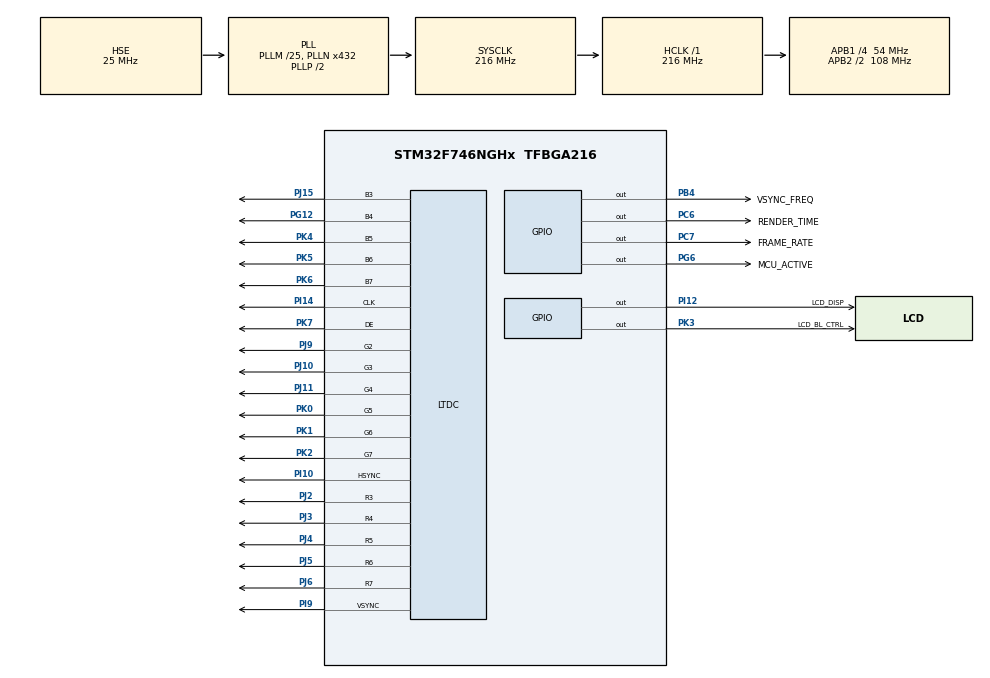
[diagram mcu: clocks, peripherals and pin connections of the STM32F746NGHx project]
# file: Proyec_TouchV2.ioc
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CORTEX_M7.CPU_DCache=Enabled
CORTEX_M7.CPU_ICache=Enabled
CORTEX_M7.default_mode_Activation=1
LTDC.ActiveH=100
LTDC.ActiveW=400
LTDC.Alpha_L0=255
LTDC.Blue_L0=0x00
LTDC.FBStartAdress_L0=0xC0000000
LTDC.Green_L0=0x00
LTDC.HBP=13
LTDC.HFP=32
LTDC.HSync=41
LTDC.ImageHeight_L0=100
LTDC.ImageWidth_L0=400
LTDC.Layers=0
LTDC.PixelFormat_L0=LTDC_PIXEL_FORMAT_RGB565
LTDC.Red_L0=0xFF
LTDC.VSync=10
LTDC.WindowX1_L0=400
LTDC.WindowY1_L0=100
Mcu.Family=STM32F7
Mcu.Name=STM32F746NGHx
Mcu.Package=TFBGA216
NVIC.DMA2D_IRQn=true\:0\:0\:false\:false\:true\:true\:true\:true
NVIC.LTDC_IRQn=true\:0\:0\:false\:false\:true\:true\:true\:true
NVIC.PriorityGroup=NVIC_PRIORITYGROUP_4
NVIC.TIM6_DAC_IRQn=true\:15\:0\:false\:false\:true\:false\:true\:true
NVIC.TimeBase=TIM6_DAC_IRQn
NVIC.TimeBaseIP=TIM6
PA13.Mode=Serial_Wire
PA13.Signal=SYS_JTMS-SWDIO
PA14.Mode=Serial_Wire
PA14.Signal=SYS_JTCK-SWCLK
PB4.GPIO_Label=VSYNC_FREQ
PB4.Signal=GPIO_Output
PC3.Signal=FMC_SDCKE0
PC6.GPIO_Label=RENDER_TIME
PC6.Signal=GPIO_Output
PC7.GPIO_Label=FRAME_RATE
PC7.Signal=GPIO_Output
PD11.Signal=QUADSPI_BK1_IO0
PD12.Signal=QUADSPI_BK1_IO1
PD13.Signal=QUADSPI_BK1_IO3
PG12.Mode=RGB565
PG12.Signal=LTDC_B4
PG6.GPIO_Label=MCU_ACTIVE
PG6.Signal=GPIO_Output
PH0/OSC_IN.Mode=HSE-External-Oscillator
PH0/OSC_IN.Signal=RCC_OSC_IN
PH1/OSC_OUT.Mode=HSE-External-Oscillator
PH1/OSC_OUT.Signal=RCC_OSC_OUT
PI10.Mode=RGB565
PI10.Signal=LTDC_HSYNC
PI12.GPIO_Label=LCD_DISP
PI12.PinState=GPIO_PIN_SET
PI12.Signal=GPIO_Output
PI14.Mode=RGB565
PI14.Signal=LTDC_CLK
PI15.Signal=LTDC_R0
PI9.Mode=RGB565
PI9.Signal=LTDC_VSYNC
PJ0.Signal=LTDC_R1
PJ1.Signal=LTDC_R2
PJ10.Mode=RGB565
PJ10.Signal=LTDC_G3
PJ11.Mode=RGB565
PJ11.Signal=LTDC_G4
PJ14.Signal=LTDC_B2
PJ15.Mode=RGB565
PJ15.Signal=LTDC_B3
PJ2.Mode=RGB565
PJ2.Signal=LTDC_R3
PJ3.Mode=RGB565
PJ3.Signal=LTDC_R4
PJ4.Mode=RGB565
PJ4.Signal=LTDC_R5
PJ5.Mode=RGB565
PJ5.Signal=LTDC_R6
PJ6.Mode=RGB565
PJ6.Signal=LTDC_R7
PJ7.Signal=LTDC_G0
PJ8.Signal=LTDC_G1
PJ9.Mode=RGB565
PJ9.Signal=LTDC_G2
PK0.Mode=RGB565
PK0.Signal=LTDC_G5
PK1.Mode=RGB565
PK1.Signal=LTDC_G6
PK2.Mode=RGB565
PK2.Signal=LTDC_G7
PK3.GPIO_Label=LCD_BL_CTRL
PK3.PinState=GPIO_PIN_SET
PK3.Signal=GPIO_Output
PK4.Mode=RGB565
PK4.Signal=LTDC_B5
PK5.Mode=RGB565
PK5.Signal=LTDC_B6
PK6.Mode=RGB565
PK6.Signal=LTDC_B7
PK7.Mode=RGB565
PK7.Signal=LTDC_DE
ProjectManager.HeapSize=0x200
ProjectManager.StackSize=0x400
ProjectManager.TargetToolchain=STM32CubeIDE
RCC.AHBFreq_Value=216000000
RCC.APB1CLKDivider=RCC_HCLK_DIV4
RCC.APB1Freq_Value=54000000
RCC.APB1TimFreq_Value=108000000
RCC.APB2CLKDivider=RCC_HCLK_DIV2
RCC.APB2Freq_Value=108000000
RCC.APB2TimFreq_Value=216000000
RCC.CortexFreq_Value=216000000
RCC.HCLKFreq_Value=216000000
RCC.HSE_VALUE=25000000
RCC.HSI_VALUE=16000000
RCC.LSE_VALUE=32768
RCC.PLLM=25
RCC.PLLN=432
RCC.PLLSAIR=5
RCC.PLLSAIRDiv=RCC_PLLSAIDIVR_4
RCC.PLLSourceVirtual=RCC_PLLSOURCE_HSE
RCC.SYSCLKFreq_VALUE=216000000
RCC.SYSCLKSource=RCC_SYSCLKSOURCE_PLLCLK
RCC.USBFreq_Value=216000000
RCC.VCOOutputFreq_Value=432000000
STMicroelectronics.X-CUBE-TOUCHGFX.4.24.0.tgfx_display_interface=disp_ltdc
STMicroelectronics.X-CUBE-TOUCHGFX.4.24.0.tgfx_hardware_accelerator=dma_2d
STMicroelectronics.X-CUBE-TOUCHGFX.4.24.0.tgfx_oswrapper=CMSIS V2
STMicroelectronics.X-CUBE-TOUCHGFX.4.24.0.tgfx_vector_rendering=Disabled
STMicroelectronics.X-CUBE-TOUCHGFX.4.24.0.tgfx_video=Disabled
STMicroelectronics.X-CUBE-TOUCHGFX.4.24.0.tgfx_video_height=272
STMicroelectronics.X-CUBE-TOUCHGFX.4.24.0.tgfx_video_strategy=2
STMicroelectronics.X-CUBE-TOUCHGFX.4.24.0.tgfx_video_width=480
STMicroelectronics.X-CUBE-TOUCHGFX.4.24.0.tgfx_vsync=vsync_ltdc
STMicroelectronics.X-CUBE-TOUCHGFX.4.24.0_IsPackSelfContextualization=true
VP_CRC_VS_CRC.Mode=CRC_Activate
VP_DMA2D_VS_DMA2D.Mode=DMA2D_Activate
VP_SYS_VS_tim6.Mode=TIM6
board=custom

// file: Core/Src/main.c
/* USER CODE BEGIN Header */
/**
  ******************************************************************************
  * @file           : main.c
  * @brief          : Main program body
  ******************************************************************************
  * @attention
  *
  * Copyright (c) 2024 STMicroelectronics.
  * All rights reserved.
  *
  * This software is licensed under terms that can be found in the LICENSE file
  * in the root directory of this software component.
  * If no LICENSE file comes with this software, it is provided AS-IS.
  *
  ******************************************************************************
  */
/* USER CODE END Header */
#include "main.h"

CRC_HandleTypeDef hcrc;

DMA2D_HandleTypeDef hdma2d;

LTDC_HandleTypeDef hltdc;

/* USER CODE BEGIN PV */

uint16_t framebuffer[400*100];  //16 bpp framebuffe

/* USER CODE END PV */

void SystemClock_Config(void);
static void MPU_Config(void);
static void MX_GPIO_Init(void);
static void MX_CRC_Init(void);
static void MX_DMA2D_Init(void);
static void MX_LTDC_Init(void);

int main(void)
{

  /* MPU Configuration--------------------------------------------------------*/
  MPU_Config();

  /* Enable the CPU Cache */

  /* Enable I-Cache---------------------------------------------------------*/
  SCB_EnableICache();

  /* Enable D-Cache---------------------------------------------------------*/
  SCB_EnableDCache();

  /* MCU Configuration--------------------------------------------------------*/

  /* Reset of all peripherals, Initializes the Flash interface and the Systick. */
  HAL_Init();

  /* Configure the system clock */
  SystemClock_Config();

  /* Initialize all configured peripherals */
  MX_GPIO_Init();
  MX_CRC_Init();
  MX_DMA2D_Init();
  MX_LTDC_Init();
  /* USER CODE BEGIN 2 */
  HAL_LTDC_SetAddress(&hltdc, (uint32_t)framebuffer, LTDC_LAYER_1);
  LTDC->IER |= LTDC_IER_LIE; // Enable LTDC interrupts
  /* USER CODE END 2 */

  /* Infinite loop */
  while (1)
  {

  }
}

void SystemClock_Config(void)
{
  RCC_OscInitTypeDef RCC_OscInitStruct = {0};
  RCC_ClkInitTypeDef RCC_ClkInitStruct = {0};

  /** Configure the main internal regulator output voltage
  */
  __HAL_RCC_PWR_CLK_ENABLE();
  __HAL_PWR_VOLTAGESCALING_CONFIG(PWR_REGULATOR_VOLTAGE_SCALE1);

  /** Initializes the RCC Oscillators according to the specified parameters
  * in the RCC_OscInitTypeDef structure.
  */
  RCC_OscInitStruct.OscillatorType = RCC_OSCILLATORTYPE_HSE;
  RCC_OscInitStruct.HSEState = RCC_HSE_ON;
  RCC_OscInitStruct.PLL.PLLState = RCC_PLL_ON;
  RCC_OscInitStruct.PLL.PLLSource = RCC_PLLSOURCE_HSE;
  RCC_OscInitStruct.PLL.PLLM = 25;
  RCC_OscInitStruct.PLL.PLLN = 432;
  RCC_OscInitStruct.PLL.PLLP = RCC_PLLP_DIV2;
  RCC_OscInitStruct.PLL.PLLQ = 2;
  if (HAL_RCC_OscConfig(&RCC_OscInitStruct) != HAL_OK)
  {
    Error_Handler();
  }

  /** Activate the Over-Drive mode
  */
  if (HAL_PWREx_EnableOverDrive() != HAL_OK)
  {
    Error_Handler();
  }

  /** Initializes the CPU, AHB and APB buses clocks
  */
  RCC_ClkInitStruct.ClockType = RCC_CLOCKTYPE_HCLK|RCC_CLOCKTYPE_SYSCLK
                              |RCC_CLOCKTYPE_PCLK1|RCC_CLOCKTYPE_PCLK2;
  RCC_ClkInitStruct.SYSCLKSource = RCC_SYSCLKSOURCE_PLLCLK;
  RCC_ClkInitStruct.AHBCLKDivider = RCC_SYSCLK_DIV1;
  RCC_ClkInitStruct.APB1CLKDivider = RCC_HCLK_DIV4;
  RCC_ClkInitStruct.APB2CLKDivider = RCC_HCLK_DIV2;

  if (HAL_RCC_ClockConfig(&RCC_ClkInitStruct, FLASH_LATENCY_7) != HAL_OK)
  {
    Error_Handler();
  }
}

static void MX_CRC_Init(void)
{

  hcrc.Instance = CRC;
  hcrc.Init.DefaultPolynomialUse = DEFAULT_POLYNOMIAL_ENABLE;
  hcrc.Init.DefaultInitValueUse = DEFAULT_INIT_VALUE_ENABLE;
  hcrc.Init.InputDataInversionMode = CRC_INPUTDATA_INVERSION_NONE;
  hcrc.Init.OutputDataInversionMode = CRC_OUTPUTDATA_INVERSION_DISABLE;
  hcrc.InputDataFormat = CRC_INPUTDATA_FORMAT_BYTES;
  if (HAL_CRC_Init(&hcrc) != HAL_OK)
  {
    Error_Handler();
  }

}

static void MX_DMA2D_Init(void)
{

  hdma2d.Instance = DMA2D;
  hdma2d.Init.Mode = DMA2D_M2M;
  hdma2d.Init.ColorMode = DMA2D_OUTPUT_ARGB8888;
  hdma2d.Init.OutputOffset = 0;
  hdma2d.LayerCfg[1].InputOffset = 0;
  hdma2d.LayerCfg[1].InputColorMode = DMA2D_INPUT_ARGB8888;
  hdma2d.LayerCfg[1].AlphaMode = DMA2D_NO_MODIF_ALPHA;
  hdma2d.LayerCfg[1].InputAlpha = 0;
  if (HAL_DMA2D_Init(&hdma2d) != HAL_OK)
  {
    Error_Handler();
  }
  if (HAL_DMA2D_ConfigLayer(&hdma2d, 1) != HAL_OK)
  {
    Error_Handler();
  }

}

static void MX_LTDC_Init(void)
{

  LTDC_LayerCfgTypeDef pLayerCfg = {0};

  hltdc.Instance = LTDC;
  hltdc.Init.HSPolarity = LTDC_HSPOLARITY_AL;
  hltdc.Init.VSPolarity = LTDC_VSPOLARITY_AL;
  hltdc.Init.DEPolarity = LTDC_DEPOLARITY_AL;
  hltdc.Init.PCPolarity = LTDC_PCPOLARITY_IPC;
  hltdc.Init.HorizontalSync = 40;
  hltdc.Init.VerticalSync = 9;
  hltdc.Init.AccumulatedHBP = 53;
  hltdc.Init.AccumulatedVBP = 11;
  hltdc.Init.AccumulatedActiveW = 453;
  hltdc.Init.AccumulatedActiveH = 111;
  hltdc.Init.TotalWidth = 485;
  hltdc.Init.TotalHeigh = 113;
  hltdc.Init.Backcolor.Blue = 0;
  hltdc.Init.Backcolor.Green = 0;
  hltdc.Init.Backcolor.Red = 0;
  if (HAL_LTDC_Init(&hltdc) != HAL_OK)
  {
    Error_Handler();
  }
  pLayerCfg.WindowX0 = 0;
  pLayerCfg.WindowX1 = 400;
  pLayerCfg.WindowY0 = 0;
  pLayerCfg.WindowY1 = 100;
  pLayerCfg.PixelFormat = LTDC_PIXEL_FORMAT_RGB565;
  pLayerCfg.Alpha = 255;
  pLayerCfg.Alpha0 = 0;
  pLayerCfg.BlendingFactor1 = LTDC_BLENDING_FACTOR1_CA;
  pLayerCfg.BlendingFactor2 = LTDC_BLENDING_FACTOR2_CA;
  pLayerCfg.FBStartAdress = 0xC0000000;
  pLayerCfg.ImageWidth = 400;
  pLayerCfg.ImageHeight = 100;
  pLayerCfg.Backcolor.Blue = 0x00;
  pLayerCfg.Backcolor.Green = 0x00;
  pLayerCfg.Backcolor.Red = 0xFF;
  if (HAL_LTDC_ConfigLayer(&hltdc, &pLayerCfg, 0) != HAL_OK)
  {
    Error_Handler();
  }

}

static void MX_GPIO_Init(void)
{
  GPIO_InitTypeDef GPIO_InitStruct = {0};

  /* GPIO Ports Clock Enable */
  __HAL_RCC_GPIOB_CLK_ENABLE();
  __HAL_RCC_GPIOA_CLK_ENABLE();
  __HAL_RCC_GPIOK_CLK_ENABLE();
  __HAL_RCC_GPIOG_CLK_ENABLE();
  __HAL_RCC_GPIOJ_CLK_ENABLE();
  __HAL_RCC_GPIOI_CLK_ENABLE();
  __HAL_RCC_GPIOH_CLK_ENABLE();
  __HAL_RCC_GPIOC_CLK_ENABLE();
  __HAL_RCC_GPIOD_CLK_ENABLE();

  /*Configure GPIO pin Output Level */
  HAL_GPIO_WritePin(VSYNC_FREQ_GPIO_Port, VSYNC_FREQ_Pin, GPIO_PIN_RESET);

  /*Configure GPIO pin Output Level */
  HAL_GPIO_WritePin(LCD_BL_CTRL_GPIO_Port, LCD_BL_CTRL_Pin, GPIO_PIN_SET);

  /*Configure GPIO pin Output Level */
  HAL_GPIO_WritePin(LCD_DISP_GPIO_Port, LCD_DISP_Pin, GPIO_PIN_SET);

  /*Configure GPIO pin Output Level */
  HAL_GPIO_WritePin(GPIOC, FRAME_RATE_Pin|RENDER_TIME_Pin, GPIO_PIN_RESET);

  /*Configure GPIO pin Output Level */
  HAL_GPIO_WritePin(MCU_ACTIVE_GPIO_Port, MCU_ACTIVE_Pin, GPIO_PIN_RESET);

  /*Configure GPIO pin : VSYNC_FREQ_Pin */
  GPIO_InitStruct.Pin = VSYNC_FREQ_Pin;
  GPIO_InitStruct.Mode = GPIO_MODE_OUTPUT_PP;
  GPIO_InitStruct.Pull = GPIO_NOPULL;
  GPIO_InitStruct.Speed = GPIO_SPEED_FREQ_LOW;
  HAL_GPIO_Init(VSYNC_FREQ_GPIO_Port, &GPIO_InitStruct);

  /*Configure GPIO pin : LCD_BL_CTRL_Pin */
  GPIO_InitStruct.Pin = LCD_BL_CTRL_Pin;
  GPIO_InitStruct.Mode = GPIO_MODE_OUTPUT_PP;
  GPIO_InitStruct.Pull = GPIO_NOPULL;
  GPIO_InitStruct.Speed = GPIO_SPEED_FREQ_LOW;
  HAL_GPIO_Init(LCD_BL_CTRL_GPIO_Port, &GPIO_InitStruct);

  /*Configure GPIO pin : LCD_DISP_Pin */
  GPIO_InitStruct.Pin = LCD_DISP_Pin;
  GPIO_InitStruct.Mode = GPIO_MODE_OUTPUT_PP;
  GPIO_InitStruct.Pull = GPIO_NOPULL;
  GPIO_InitStruct.Speed = GPIO_SPEED_FREQ_LOW;
  HAL_GPIO_Init(LCD_DISP_GPIO_Port, &GPIO_InitStruct);

  /*Configure GPIO pins : FRAME_RATE_Pin RENDER_TIME_Pin */
  GPIO_InitStruct.Pin = FRAME_RATE_Pin|RENDER_TIME_Pin;
  GPIO_InitStruct.Mode = GPIO_MODE_OUTPUT_PP;
  GPIO_InitStruct.Pull = GPIO_NOPULL;
  GPIO_InitStruct.Speed = GPIO_SPEED_FREQ_LOW;
  HAL_GPIO_Init(GPIOC, &GPIO_InitStruct);

  /*Configure GPIO pin : MCU_ACTIVE_Pin */
  GPIO_InitStruct.Pin = MCU_ACTIVE_Pin;
  GPIO_InitStruct.Mode = GPIO_MODE_OUTPUT_PP;
  GPIO_InitStruct.Pull = GPIO_NOPULL;
  GPIO_InitStruct.Speed = GPIO_SPEED_FREQ_LOW;
  HAL_GPIO_Init(MCU_ACTIVE_GPIO_Port, &GPIO_InitStruct);

  /*Configure GPIO pin : PC3 */
  GPIO_InitStruct.Pin = GPIO_PIN_3;
  GPIO_InitStruct.Mode = GPIO_MODE_AF_PP;
  GPIO_InitStruct.Pull = GPIO_NOPULL;
  GPIO_InitStruct.Speed = GPIO_SPEED_FREQ_VERY_HIGH;
  GPIO_InitStruct.Alternate = GPIO_AF12_FMC;
  HAL_GPIO_Init(GPIOC, &GPIO_InitStruct);

  /*Configure GPIO pins : PD12 PD13 PD11 */
  GPIO_InitStruct.Pin = GPIO_PIN_12|GPIO_PIN_13|GPIO_PIN_11;
  GPIO_InitStruct.Mode = GPIO_MODE_AF_PP;
  GPIO_InitStruct.Pull = GPIO_NOPULL;
  GPIO_InitStruct.Speed = GPIO_SPEED_FREQ_VERY_HIGH;
  GPIO_InitStruct.Alternate = GPIO_AF9_QUADSPI;
  HAL_GPIO_Init(GPIOD, &GPIO_InitStruct);

}

 /* MPU Configuration */

void MPU_Config(void)
{
  MPU_Region_InitTypeDef MPU_InitStruct = {0};

  /* Disables the MPU */
  HAL_MPU_Disable();

  /** Initializes and configures the Region and the memory to be protected
  */
  MPU_InitStruct.Enable = MPU_REGION_ENABLE;
  MPU_InitStruct.Number = MPU_REGION_NUMBER0;
  MPU_InitStruct.BaseAddress = 0x0;
  MPU_InitStruct.Size = MPU_REGION_SIZE_4GB;
  MPU_InitStruct.SubRegionDisable = 0x87;
  MPU_InitStruct.TypeExtField = MPU_TEX_LEVEL0;
  MPU_InitStruct.AccessPermission = MPU_REGION_NO_ACCESS;
  MPU_InitStruct.DisableExec = MPU_INSTRUCTION_ACCESS_DISABLE;
  MPU_InitStruct.IsShareable = MPU_ACCESS_SHAREABLE;
  MPU_InitStruct.IsCacheable = MPU_ACCESS_NOT_CACHEABLE;
  MPU_InitStruct.IsBufferable = MPU_ACCESS_NOT_BUFFERABLE;

  HAL_MPU_ConfigRegion(&MPU_InitStruct);
  /* Enables the MPU */
  HAL_MPU_Enable(MPU_PRIVILEGED_DEFAULT);

}

void HAL_TIM_PeriodElapsedCallback(TIM_HandleTypeDef *htim)
{
  if (htim->Instance == TIM6) {
    HAL_IncTick();
  }
}

void Error_Handler(void)
{
  __disable_irq();
  while (1)
  {
  }
}
